VERSION ""

NS_ :

BS_:

BU_: DAS HANDCART DAS STEER STEER INVERTER_L HANDCART HANDCART DAS DAS STEER DAS BMS_HV STEER STEER HANDCART DAS TLM BMS_HV STEER STEER STEER DAS TLM DAS DAS HANDCART STEER STEER BMS_HV DAS BMS_HW HANDCART STEER DAS BMS_HV DAS STEER TLM DAS BMS_LW HANDCART STEER DAS STEER DAS STEER DAS STEER TLM DAS DAS DAS STEER STEER STEER STEER DAS BMS_HW DAS TLM DAS BMS_LV STEER DAS DAS TLM STEER BMS_LV TLM DAS BMS_HV STEER BMS_LV BMS_LV DATA_LOGGER DAS STEER BMS_HV STEER DAS BMS_LV TLM DAS BMS_HV STEER BMS_LV BMS_LV STEER DAS BMS_HV TLM STEER TLM BMS_LV STEER DAS STEER STEER TLM STEER BMS_HV BMS_LV DAS STEER STEER BMS_LV HANDCART HANDCART DAS BMS_HV BMS_LV DAS BMS_HV BMS_LV INVERTER_L STEER DAS HANDCART STEER BMS_HV BMS_HV BMS_LV DAS BMS_HV DAS STEER HANDCART BMS_HV STEER HANDCART INVERTER_L HANDCART TLM BMS_HV BMS_HV BMS_LV DAS HANDCART HANDCART DAS STEER BMS_HV STEER HANDCART HANDCART TLM BMS_HV BMS_HV BMS_LV DAS HANDCART DAS STEER BMS_HV STEER HANDCART HANDCART TLM BMS_HV BMS_HV BMS_HV DAS HANDCART DAS STEER BMS_HV STEER HANDCART HANDCART TLM HANDCART HANDCART BMS_HV BMS_HV BMS_LV HANDCART BMS_LV BMS_HV BMS_HV TLM HANDCART HANDCART STEER BMS_HV BMS_HV TLM HANDCART HANDCART BMS_HV BMS_HV BMS_HV HANDCART DAS HANDCART HANDCART BMS_HV STEER BMS_LV HANDCART BMS_HV HANDCART TLM DAS BMS_HV BMS_HV STEER HANDCART HANDCART BMS_HV BMS_HV HANDCART DAS HANDCART BMS_HV STEER DAS DAS BMS_HV HANDCART STEER DAS DAS DAS STEER HANDCART INVERTER_L BMS_HV DAS DAS DAS HANDCART STEER HANDCART STEER BMS_HV

BO_ 1818 NLG5_DIAG_TX: 8 NLG5
 SG_ LAD_D_ParamRp : 7|64@0+ (1,0) [0|0] "" Vector__XXX

BO_ 1816 NLG5_DIAG_RX: 8 Control
 SG_ LAD_D_ParamRq : 7|64@0+ (1,0) [0|0] "" Vector__XXX

BO_ 1556 NLG5_ERR: 5 NLG5
 SG_ NLG5_W_SC_M : 32|1@0+ (1,0) [0|0] ""  Control
 SG_ NLG5_W_OD : 33|1@0+ (1,0) [0|0] "" Vector__XXX
 SG_ NLG5_W_CM_NA : 35|1@0+ (1,0) [0|0] "" Vector__XXX
 SG_ NLG5_W_C_VOR : 36|1@0+ (1,0) [0|1] ""  Control
 SG_ NLG5_W_PL_IT : 37|1@0+ (1,0) [0|1] ""  Control
 SG_ NLG5_W_PL_BV : 38|1@0+ (1,0) [0|1] ""  Control
 SG_ NLG5_W_PL_MV : 39|1@0+ (1,0) [0|1] ""  Control
 SG_ NLG5_E_SDT_CT : 26|1@0+ (1,0) [0|1] ""  Control
 SG_ NLG5_E_SDT_AH : 27|1@0+ (1,0) [0|1] ""  Control
 SG_ NLG5_E_SDT_BV : 28|1@0+ (1,0) [0|1] ""  Control
 SG_ NLG5_E_SDT_BT : 29|1@0+ (1,0) [0|1] ""  Control
 SG_ NLG5_E_C_RX : 30|1@0+ (1,0) [0|1] ""  Control
 SG_ NLG5_E_C_TX : 31|1@0+ (1,0) [0|1] ""  Control
 SG_ NLG5_E_C_OFF : 16|1@0+ (1,0) [0|1] ""  Control
 SG_ NLG5_E_C_TO : 17|1@0+ (1,0) [0|1] ""  Control
 SG_ NLG5_E_INIT : 18|1@0+ (1,0) [0|1] ""  Control
 SG_ NLG5_E_WDT : 19|1@0+ (1,0) [0|1] ""  Control
 SG_ NLG5_E_EP_CRC : 20|1@0+ (1,0) [0|1] ""  Control
 SG_ NLG5_E_ES_CRC : 21|1@0+ (1,0) [0|1] ""  Control
 SG_ NLG5_E_NV_CRC : 22|1@0+ (1,0) [0|1] ""  Control
 SG_ NLG5_E_F_CRC : 23|1@0+ (1,0) [0|1] ""  Control
 SG_ NLG5_E_T_EXT3 : 8|1@0+ (1,0) [0|1] ""  Control
 SG_ NLG5_E_T_EXT2 : 9|1@0+ (1,0) [0|1] ""  Control
 SG_ NLG5_E_T_EXT1 : 10|1@0+ (1,0) [0|1] ""  Control
 SG_ NLG5_E_T_TR : 11|1@0+ (1,0) [0|1] ""  Control
 SG_ NLG5_E_T_DIO : 12|1@0+ (1,0) [0|1] ""  Control
 SG_ NLG5_E_T_POW : 13|1@0+ (1,0) [0|1] ""  Control
 SG_ NLG5_E_T_C : 14|1@0+ (1,0) [0|1] ""  Control
 SG_ NLG5_E_B_P : 15|1@0+ (1,0) [0|1] ""  Control
 SG_ NLG5_E_MF : 0|1@0+ (1,0) [0|1] ""  Control
 SG_ NLG5_E_OF : 1|1@0+ (1,0) [0|1] ""  Control
 SG_ NLG5_E_P_MV : 2|1@0+ (1,0) [0|1] ""  Control
 SG_ NLG5_E_P_OM : 3|1@0+ (1,0) [0|1] ""  Control
 SG_ NLG5_E_SC : 4|1@0+ (1,0) [0|1] ""  Control
 SG_ NLG5_E_MOV_I : 5|1@0+ (1,0) [0|1] ""  Control
 SG_ NLG5_E_MOV_II : 6|1@0+ (1,0) [0|1] ""  Control
 SG_ NLG5_E_OOV : 7|1@0+ (1,0) [0|1] ""  Control

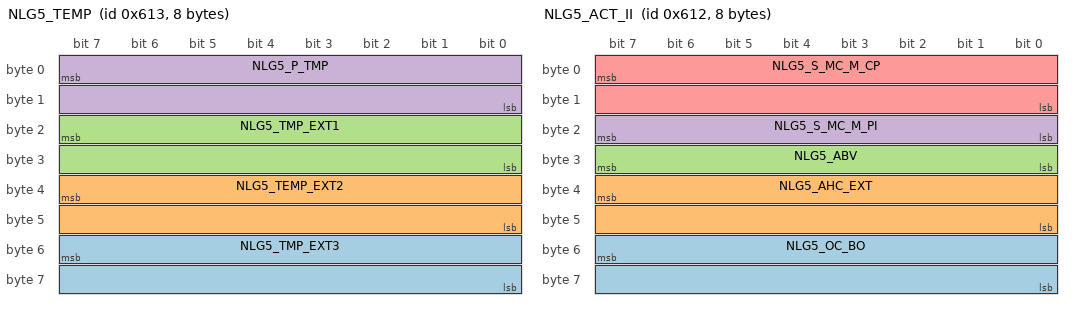
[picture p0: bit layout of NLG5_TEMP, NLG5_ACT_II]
BO_ 1555 NLG5_TEMP: 8 NLG5
 SG_ NLG5_TMP_EXT3 : 55|16@0- (0.1,0) [-40|300] "°C"  Control
 SG_ NLG5_TEMP_EXT2 : 39|16@0- (0.1,0) [-40|300] "°C"  Control
 SG_ NLG5_TMP_EXT1 : 23|16@0- (0.1,0) [-40|300] "°C"  Control
 SG_ NLG5_P_TMP : 7|16@0- (0.1,0) [-40|300] "°C"  Control

BO_ 1554 NLG5_ACT_II: 8 NLG5
 SG_ NLG5_OC_BO : 55|16@0+ (0.01,0) [0|50] "A"  Control
 SG_ NLG5_AHC_EXT : 39|16@0- (0.01,0) [-327.68|327.67] "Ah"  Control
 SG_ NLG5_ABV : 31|8@0+ (0.1,0) [0|25] "V"  Control
 SG_ NLG5_S_MC_M_PI : 23|8@0+ (0.1,0) [0|20] "A"  Control
 SG_ NLG5_S_MC_M_CP : 7|16@0+ (0.1,0) [0|100] "A"  Control

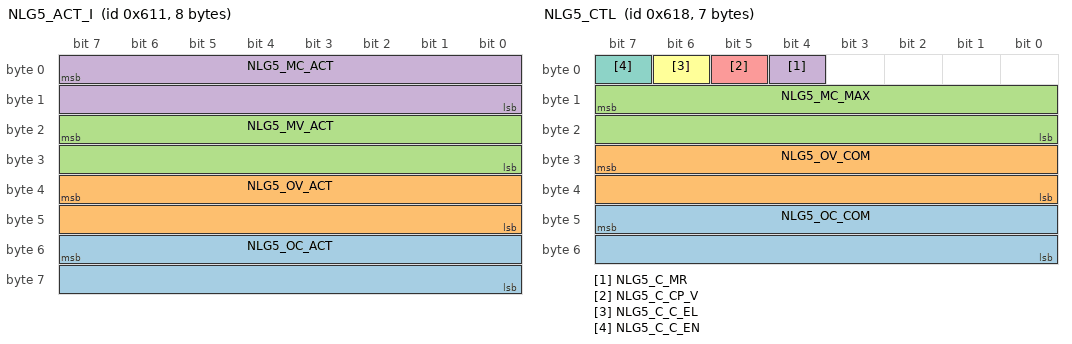
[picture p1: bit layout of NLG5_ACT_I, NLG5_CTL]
BO_ 1553 NLG5_ACT_I: 8 NLG5
 SG_ NLG5_OC_ACT : 55|16@0- (0.01,0) [0|150] "A"  Control
 SG_ NLG5_OV_ACT : 39|16@0+ (0.1,0) [0|1000] "V"  Control
 SG_ NLG5_MV_ACT : 23|16@0+ (0.1,0) [0|500] "V"  Control
 SG_ NLG5_MC_ACT : 7|16@0+ (0.01,0) [0|50] "A"  Control

BO_ 1552 NLG5_ST: 4 NLG5
 SG_ NLG5_S_AAC : 24|1@0+ (1,0) [0|1] ""  Control
 SG_ NLG5_S_L_T_BATT : 16|1@0+ (1,0) [0|1] ""  Control
 SG_ NLG5_S_L_T_TR : 17|1@0+ (1,0) [0|1] ""  Control
 SG_ NLG5_S_L_T_DIO : 18|1@0+ (1,0) [0|1] ""  Control
 SG_ NLG5_S_L_T_POW : 19|1@0+ (1,0) [0|1] ""  Control
 SG_ NLG5_S_L_T_CPRIM : 20|1@0+ (1,0) [0|1] ""  Control
 SG_ NLG5_S_L_MO_MAX : 21|1@0+ (1,0) [0|1] ""  Control
 SG_ NLG5_S_L_OC_MAX : 22|1@0+ (1,0) [0|1] ""  Control
 SG_ NLG5_S_L_MC_MAX : 23|1@0+ (1,0) [0|1] ""  Control
 SG_ NLG5_S_L_PMAX : 8|1@0+ (1,0) [0|1] ""  Control
 SG_ NLG5_S_L_CP : 9|1@0+ (1,0) [0|1] ""  Control
 SG_ NLG5_S_L_PI : 10|1@0+ (1,0) [0|1] ""  Control
 SG_ NLG5_S_L_MC : 11|1@0+ (1,0) [0|1] ""  Control
 SG_ NLG5_S_L_OC : 12|1@0+ (1,0) [0|1] ""  Control
 SG_ NLG5_S_L_OV : 13|1@0+ (1,0) [0|1] ""  Control
 SG_ NLG5_S_BPD_II : 14|1@0+ (1,0) [0|1] ""  Control
 SG_ NLG5_S_BPD_I : 15|1@0+ (1,0) [0|1] ""  Control
 SG_ NLG5_S_CP_DT : 0|1@0+ (1,0) [0|1] ""  Control
 SG_ NLG5_S_UM_II : 1|1@0+ (1,0) [0|1] ""  Control
 SG_ NLG5_S_UM_I : 2|1@0+ (1,0) [0|1] ""  Control
 SG_ NLG5_S_EUM : 3|1@0+ (1,0) [0|1] ""  Control
 SG_ NLG5_S_FAN : 4|1@0+ (1,0) [0|1] ""  Control
 SG_ NLG5_S_WAR : 5|1@0+ (1,0) [0|1] ""  Control
 SG_ NLG5_S_ERR : 6|1@0+ (1,0) [0|1] ""  Control
 SG_ NLG5_S_HE : 7|1@0+ (1,0) [0|1] ""  Control

BO_ 1560 NLG5_CTL: 7 Control
 SG_ NLG5_OC_COM : 47|16@0+ (0.1,0) [0|150] "A"  NLG5
 SG_ NLG5_OV_COM : 31|16@0+ (0.1,0) [0|1000] "V"  NLG5
 SG_ NLG5_MC_MAX : 15|16@0+ (0.1,0) [0|50] "A"  NLG5
 SG_ NLG5_C_MR : 4|1@0+ (1,0) [0|1] ""  NLG5
 SG_ NLG5_C_CP_V : 5|1@0+ (1,0) [0|1] ""  NLG5
 SG_ NLG5_C_C_EL : 6|1@0+ (1,0) [0|1] ""  NLG5
 SG_ NLG5_C_C_EN : 7|1@0+ (1,0) [0|1] ""  NLG5

BO_ 0 BMS_HV_JMP_TO_BLT: 0 Vector__XXX

BO_ 1 FLASH_BMS_HV_TX: 0 Vector__XXX

BO_ 2 FLASH_BMS_HV_RX: 0 Vector__XXX

BO_ 3 HV_CAN_FORWARD: 1 Vector__XXX
 SG_ can_forward_set : 0|1@1+ (1,0) [0|1] "" Vector__XXX

BO_ 4 FLASH_CELLBOARD_0_TX: 0 Vector__XXX

BO_ 5 FLASH_CELLBOARD_0_RX: 0 Vector__XXX

BO_ 6 FLASH_CELLBOARD_1_TX: 0 Vector__XXX

BO_ 7 FLASH_CELLBOARD_1_RX: 0 Vector__XXX

BO_ 8 FLASH_CELLBOARD_2_TX: 0 Vector__XXX

BO_ 9 FLASH_CELLBOARD_2_RX: 0 Vector__XXX

BO_ 10 FLASH_CELLBOARD_3_TX: 0 Vector__XXX

BO_ 11 FLASH_CELLBOARD_3_RX: 0 Vector__XXX

BO_ 12 FLASH_CELLBOARD_4_TX: 0 Vector__XXX

BO_ 13 FLASH_CELLBOARD_4_RX: 0 Vector__XXX

BO_ 14 FLASH_CELLBOARD_5_TX: 0 Vector__XXX

BO_ 15 FLASH_CELLBOARD_5_RX: 0 Vector__XXX

BO_ 16 BMS_LV_JMP_TO_BLT: 0 Vector__XXX

BO_ 17 FLASH_BMS_LV_TX: 0 Vector__XXX

BO_ 18 FLASH_BMS_LV_RX: 0 Vector__XXX

BO_ 19 ECU_JMP_TO_BLT: 0 Vector__XXX

BO_ 20 FLASH_ECU_TX: 0 Vector__XXX

BO_ 21 FLASH_ECU_RX: 0 Vector__XXX

BO_ 22 STEERING_JMP_TO_BLT: 0 Vector__XXX

BO_ 23 FLASH_STEERING_TX: 0 Vector__XXX

BO_ 24 FLASH_STEERING_RX: 0 Vector__XXX

BO_ 700 STEER_VERSION: 8 Vector__XXX
 SG_ canlib_build_time : 32|32@1+ (1,0) [0|4294967295] "" Vector__XXX
 SG_ component_build_time : 0|32@1+ (1,0) [0|4294967295] "" Vector__XXX

BO_ 701 DAS_VERSION: 8 Vector__XXX
 SG_ canlib_build_time : 32|32@1+ (1,0) [0|4294967295] "" Vector__XXX
 SG_ component_build_time : 0|32@1+ (1,0) [0|4294967295] "" Vector__XXX

BO_ 702 MAINBOARD_VERSION: 8 Vector__XXX
 SG_ canlib_build_time : 32|32@1+ (1,0) [0|4294967295] "" Vector__XXX
 SG_ component_build_time : 0|32@1+ (1,0) [0|4294967295] "" Vector__XXX

BO_ 703 LV_VERSION: 8 Vector__XXX
 SG_ canlib_build_time : 32|32@1+ (1,0) [0|4294967295] "" Vector__XXX
 SG_ component_build_time : 0|32@1+ (1,0) [0|4294967295] "" Vector__XXX

BO_ 704 TLM_VERSION: 8 Vector__XXX
 SG_ canlib_build_time : 32|32@1+ (1,0) [0|4294967295] "" Vector__XXX
 SG_ component_build_time : 0|32@1+ (1,0) [0|4294967295] "" Vector__XXX

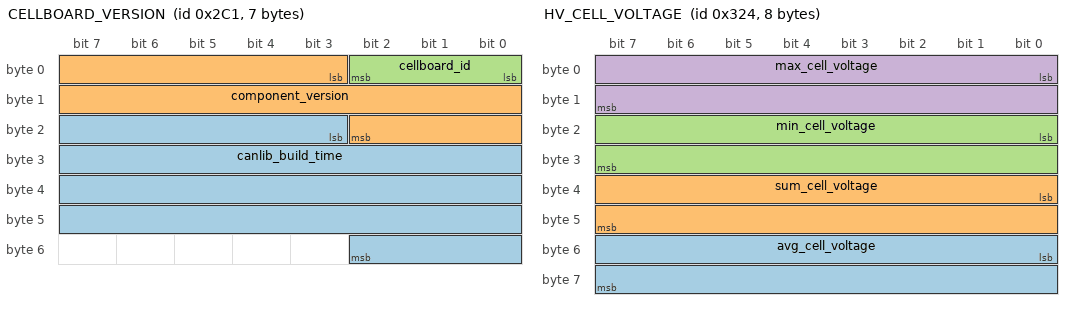
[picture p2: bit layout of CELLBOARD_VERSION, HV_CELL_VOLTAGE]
BO_ 705 CELLBOARD_VERSION: 7 Vector__XXX
 SG_ canlib_build_time : 19|32@1+ (1,0) [0|4294967295] "" Vector__XXX
 SG_ component_version : 3|16@1+ (1,0) [0|65535] "" Vector__XXX
 SG_ cellboard_id : 0|3@1+ (1,0) [0|7] "" Vector__XXX

BO_ 257 AMBIENT_TEMPERATURE: 2 Vector__XXX
 SG_ temp : 0|16@1- (1,-32768) [-32768|32767] "" Vector__XXX

BO_ 1072 DATA_LOGGER: 8 Vector__XXX
 SG_ placeholder2 : 32|32@1+ (1,0) [0|4294967295] "" Vector__XXX
 SG_ placeholder1 : 0|32@1+ (1,0) [0|4294967295] "" Vector__XXX

BO_ 265 SET_TLM_STATUS: 1 Vector__XXX
 SG_ tlm_status : 0|1@1+ (1,0) [0|1] "" Vector__XXX

BO_ 264 TLM_STATUS: 1 Vector__XXX
 SG_ tlm_status : 0|1@1+ (1,0) [0|1] "" Vector__XXX

BO_ 1801 STEER_SYSTEM_STATUS: 1 Vector__XXX
 SG_ soc_temp : 0|8@1+ (1,0) [0|255] "" Vector__XXX

BO_ 772 HV_VOLTAGE: 4 Vector__XXX
 SG_ bus_voltage : 16|16@1+ (0.9001956947162426,0) [0|460] "" Vector__XXX
 SG_ pack_voltage : 0|16@1+ (0.9001956947162426,0) [0|460] "" Vector__XXX

BO_ 804 HV_CELL_VOLTAGE: 8 Vector__XXX
 SG_ avg_cell_voltage : 48|16@1+ (7.629510948348211e-05,0) [0|5] "" Vector__XXX
 SG_ sum_cell_voltage : 32|16@1+ (0.007019150072480354,0) [0|460] "" Vector__XXX
 SG_ min_cell_voltage : 16|16@1+ (7.629510948348211e-05,0) [0|5] "" Vector__XXX
 SG_ max_cell_voltage : 0|16@1+ (7.629510948348211e-05,0) [0|5] "" Vector__XXX

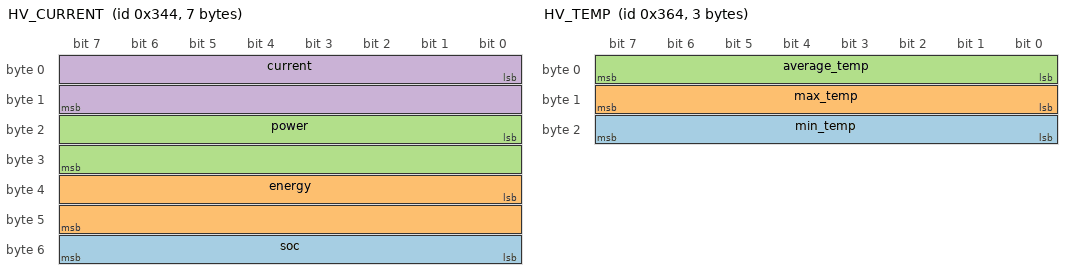
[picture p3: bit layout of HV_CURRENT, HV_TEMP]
BO_ 836 HV_CURRENT: 7 Vector__XXX
 SG_ soc : 48|8@1+ (0.39215686274509803,0) [0|100] "" Vector__XXX
 SG_ energy : 32|16@1+ (0.10681315327687495,0) [0|7000] "" Vector__XXX
 SG_ power : 16|16@1+ (0.0015259021896696422,0) [0|100] "" Vector__XXX
 SG_ current : 0|16@1+ (0.006103608758678569,-200) [-200|200] "" Vector__XXX

BO_ 868 HV_TEMP: 3 Vector__XXX
 SG_ min_temp : 16|8@1+ (0.39215686274509803,-20) [-20|80] "" Vector__XXX
 SG_ max_temp : 8|8@1+ (0.39215686274509803,-20) [-20|80] "" Vector__XXX
 SG_ average_temp : 0|8@1+ (0.39215686274509803,-20) [-20|80] "" Vector__XXX

BO_ 36 HV_ERRORS: 4 Vector__XXX
 SG_ errors_EEPROM_WRITE : 31|1@1+ (1,0) [0|1] "" Vector__XXX
 SG_ errors_EEPROM_COMM : 30|1@1+ (1,0) [0|1] "" Vector__XXX
 SG_ errors_FEEDBACK_CIRCUITRY : 29|1@1+ (1,0) [0|1] "" Vector__XXX
 SG_ errors_FEEDBACK : 28|1@1+ (1,0) [0|1] "" Vector__XXX
 SG_ errors_FANS_DISCONNECTED : 27|1@1+ (1,0) [0|1] "" Vector__XXX
 SG_ errors_CONNECTOR_DISCONNECTED : 26|1@1+ (1,0) [0|1] "" Vector__XXX
 SG_ errors_CELLBOARD_INTERNAL : 25|1@1+ (1,0) [0|1] "" Vector__XXX
 SG_ errors_CELLBOARD_COMM : 24|1@1+ (1,0) [0|1] "" Vector__XXX
 SG_ errors_INT_VOLTAGE_MISMATCH : 23|1@1+ (1,0) [0|1] "" Vector__XXX
 SG_ errors_CAN : 22|1@1+ (1,0) [0|1] "" Vector__XXX
 SG_ errors_OVER_CURRENT : 21|1@1+ (1,0) [0|1] "" Vector__XXX
 SG_ errors_CELL_OVER_TEMPERATURE : 20|1@1+ (1,0) [0|1] "" Vector__XXX
 SG_ errors_CELL_HIGH_TEMPERATURE : 19|1@1+ (1,0) [0|1] "" Vector__XXX
 SG_ errors_CELL_OVER_VOLTAGE : 18|1@1+ (1,0) [0|1] "" Vector__XXX
 SG_ errors_CELL_UNDER_VOLTAGE : 17|1@1+ (1,0) [0|1] "" Vector__XXX
 SG_ errors_CELL_LOW_VOLTAGE : 16|1@1+ (1,0) [0|1] "" Vector__XXX
 SG_ warnings_EEPROM_WRITE : 15|1@1+ (1,0) [0|1] "" Vector__XXX
 SG_ warnings_EEPROM_COMM : 14|1@1+ (1,0) [0|1] "" Vector__XXX
 SG_ warnings_FEEDBACK_CIRCUITRY : 13|1@1+ (1,0) [0|1] "" Vector__XXX
 SG_ warnings_FEEDBACK : 12|1@1+ (1,0) [0|1] "" Vector__XXX
 SG_ warnings_FANS_DISCONNECTED : 11|1@1+ (1,0) [0|1] "" Vector__XXX
 SG_ warnings_CONNECTOR_DISCONNECTED : 10|1@1+ (1,0) [0|1] "" Vector__XXX
 SG_ warnings_CELLBOARD_INTERNAL : 9|1@1+ (1,0) [0|1] "" Vector__XXX
 SG_ warnings_CELLBOARD_COMM : 8|1@1+ (1,0) [0|1] "" Vector__XXX
 SG_ warnings_INT_VOLTAGE_MISMATCH : 7|1@1+ (1,0) [0|1] "" Vector__XXX
 SG_ warnings_CAN : 6|1@1+ (1,0) [0|1] "" Vector__XXX
 SG_ warnings_OVER_CURRENT : 5|1@1+ (1,0) [0|1] "" Vector__XXX
 SG_ warnings_CELL_OVER_TEMPERATURE : 4|1@1+ (1,0) [0|1] "" Vector__XXX
 SG_ warnings_CELL_HIGH_TEMPERATURE : 3|1@1+ (1,0) [0|1] "" Vector__XXX
 SG_ warnings_CELL_OVER_VOLTAGE : 2|1@1+ (1,0) [0|1] "" Vector__XXX
 SG_ warnings_CELL_UNDER_VOLTAGE : 1|1@1+ (1,0) [0|1] "" Vector__XXX
 SG_ warnings_CELL_LOW_VOLTAGE : 0|1@1+ (1,0) [0|1] "" Vector__XXX

BO_ 260 HV_DEBUG_SIGNALS: 5 Vector__XXX
 SG_ debug_signals_ERROR_EEPROM_WRITE : 35|1@1+ (1,0) [0|1] "" Vector__XXX
 SG_ debug_signals_ERROR_EEPROM_COMM : 34|1@1+ (1,0) [0|1] "" Vector__XXX
 SG_ debug_signals_ERROR_FEEDBACK_CIRCUITRY : 33|1@1+ (1,0) [0|1] "" Vector__XXX
 SG_ debug_signals_ERROR_FEEDBACK : 32|1@1+ (1,0) [0|1] "" Vector__XXX
 SG_ debug_signals_ERROR_FANS_DISCONNECTED : 31|1@1+ (1,0) [0|1] "" Vector__XXX
 SG_ debug_signals_ERROR_CONNECTOR_DISCONNECTED : 30|1@1+ (1,0) [0|1] "" Vector__XXX
 SG_ debug_signals_ERROR_CELLBOARD_INTERNAL : 29|1@1+ (1,0) [0|1] "" Vector__XXX
 SG_ debug_signals_ERROR_CELLBOARD_COMM : 28|1@1+ (1,0) [0|1] "" Vector__XXX
 SG_ debug_signals_ERROR_INT_VOLTAGE_MISMATCH : 27|1@1+ (1,0) [0|1] "" Vector__XXX
 SG_ debug_signals_ERROR_CAN : 26|1@1+ (1,0) [0|1] "" Vector__XXX
 SG_ debug_signals_ERROR_OVER_CURRENT : 25|1@1+ (1,0) [0|1] "" Vector__XXX
 SG_ debug_signals_ERROR_CELL_OVER_TEMPERATURE : 24|1@1+ (1,0) [0|1] "" Vector__XXX
 SG_ debug_signals_ERROR_CELL_HIGH_TEMPERATURE : 23|1@1+ (1,0) [0|1] "" Vector__XXX
 SG_ debug_signals_ERROR_CELL_OVER_VOLTAGE : 22|1@1+ (1,0) [0|1] "" Vector__XXX
 SG_ debug_signals_ERROR_CELL_UNDER_VOLTAGE : 21|1@1+ (1,0) [0|1] "" Vector__XXX
 SG_ debug_signals_ERROR_CELL_LOW_VOLTAGE : 20|1@1+ (1,0) [0|1] "" Vector__XXX
 SG_ debug_signals_FEEDBACK_SD_IMD : 19|1@1+ (1,0) [0|1] "" Vector__XXX
 SG_ debug_signals_FEEDBACK_SD_BMS : 18|1@1+ (1,0) [0|1] "" Vector__XXX
 SG_ debug_signals_FEEDBACK_SD_IN : 17|1@1+ (1,0) [0|1] "" Vector__XXX
 SG_ debug_signals_FEEDBACK_SD_OUT : 16|1@1+ (1,0) [0|1] "" Vector__XXX
 SG_ debug_signals_FEEDBACK_SD_END : 15|1@1+ (1,0) [0|1] "" Vector__XXX
 SG_ debug_signals_FEEDBACK_CHECK_MUX : 14|1@1+ (1,0) [0|1] "" Vector__XXX
 SG_ debug_signals_FEEDBACK_IMD_FAULT : 13|1@1+ (1,0) [0|1] "" Vector__XXX
 SG_ debug_signals_FEEDBACK_TSP_OVER_60V_STATUS : 12|1@1+ (1,0) [0|1] "" Vector__XXX
 SG_ debug_signals_FEEDBACK_PRECHARGE_STATUS : 11|1@1+ (1,0) [0|1] "" Vector__XXX
 SG_ debug_signals_FEEDBACK_AIRN_GATE : 10|1@1+ (1,0) [0|1] "" Vector__XXX
 SG_ debug_signals_FEEDBACK_AIRP_GATE : 9|1@1+ (1,0) [0|1] "" Vector__XXX
 SG_ debug_signals_FEEDBACK_AIRP_STATUS : 8|1@1+ (1,0) [0|1] "" Vector__XXX
 SG_ debug_signals_FEEDBACK_AIRN_STATUS : 7|1@1+ (1,0) [0|1] "" Vector__XXX
 SG_ debug_signals_FEEDBACK_TS_OVER_60V_STATUS : 6|1@1+ (1,0) [0|1] "" Vector__XXX
 SG_ debug_signals_FEEDBACK_TSAL_GREEN : 5|1@1+ (1,0) [0|1] "" Vector__XXX
 SG_ debug_signals_FEEDBACK_EXT_LATCHED : 4|1@1+ (1,0) [0|1] "" Vector__XXX
 SG_ debug_signals_FEEDBACK_BMS_COCKPIT : 3|1@1+ (1,0) [0|1] "" Vector__XXX
 SG_ debug_signals_FEEDBACK_TSAL_GREEN_FAULT_LATCHED : 2|1@1+ (1,0) [0|1] "" Vector__XXX
 SG_ debug_signals_FEEDBACK_IMD_COCKPIT : 1|1@1+ (1,0) [0|1] "" Vector__XXX
 SG_ debug_signals_FEEDBACK_IMPLAUSIBILITY_DETECTED : 0|1@1+ (1,0) [0|1] "" Vector__XXX

BO_ 32 HV_FANS_OVERRIDE: 3 Vector__XXX
 SG_ fans_speed : 1|16@1+ (1.5259021896696422e-05,0) [0|1] "" Vector__XXX
 SG_ fans_override : 0|1@1+ (1,0) [0|1] "" Vector__XXX

BO_ 37 HV_CAN_FORWARD_STATUS: 1 Vector__XXX
 SG_ can_forward_status : 0|1@1+ (1,0) [0|1] "" Vector__XXX

BO_ 773 HV_FANS_OVERRIDE_STATUS: 3 Vector__XXX
 SG_ fans_speed : 1|16@1+ (1.5259021896696422e-05,0) [0|1] "" Vector__XXX
 SG_ fans_override : 0|1@1+ (1,0) [0|1] "" Vector__XXX

BO_ 771 HV_FEEDBACK_STATUS: 5 Vector__XXX
 SG_ feedback_sd_imd : 38|2@1+ (1,0) [0|3] "" Vector__XXX
 SG_ feedback_sd_bms : 36|2@1+ (1,0) [0|3] "" Vector__XXX
 SG_ feedback_sd_in : 34|2@1+ (1,0) [0|3] "" Vector__XXX
 SG_ feedback_sd_out : 32|2@1+ (1,0) [0|3] "" Vector__XXX
 SG_ feedback_sd_end : 30|2@1+ (1,0) [0|3] "" Vector__XXX
 SG_ feedback_check_mux : 28|2@1+ (1,0) [0|3] "" Vector__XXX
 SG_ feedback_imd_fault : 26|2@1+ (1,0) [0|3] "" Vector__XXX
 SG_ feedback_tsp_over_60v_status : 24|2@1+ (1,0) [0|3] "" Vector__XXX
 SG_ feedback_precharge_status : 22|2@1+ (1,0) [0|3] "" Vector__XXX
 SG_ feedback_airn_gate : 20|2@1+ (1,0) [0|3] "" Vector__XXX
 SG_ feedback_airp_gate : 18|2@1+ (1,0) [0|3] "" Vector__XXX
 SG_ feedback_airp_status : 16|2@1+ (1,0) [0|3] "" Vector__XXX
 SG_ feedback_airn_status : 14|2@1+ (1,0) [0|3] "" Vector__XXX
 SG_ feedback_ts_over_60v_status : 12|2@1+ (1,0) [0|3] "" Vector__XXX
 SG_ feedback_tsal_green : 10|2@1+ (1,0) [0|3] "" Vector__XXX
 SG_ feedback_ext_latched : 8|2@1+ (1,0) [0|3] "" Vector__XXX
 SG_ feedback_bms_cockpit : 6|2@1+ (1,0) [0|3] "" Vector__XXX
 SG_ feedback_tsal_green_fault_latched : 4|2@1+ (1,0) [0|3] "" Vector__XXX
 SG_ feedback_imd_cockpit : 2|2@1+ (1,0) [0|3] "" Vector__XXX
 SG_ feedback_implausibility_detected : 0|2@1+ (1,0) [0|3] "" Vector__XXX

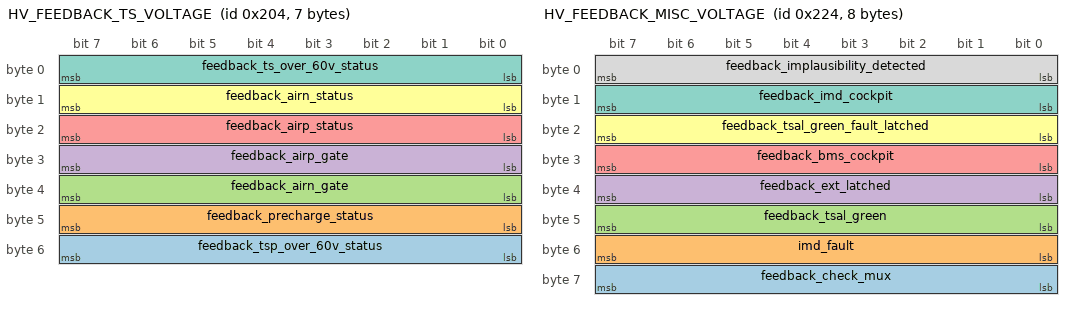
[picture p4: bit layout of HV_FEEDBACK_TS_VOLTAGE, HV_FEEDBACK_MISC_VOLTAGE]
BO_ 516 HV_FEEDBACK_TS_VOLTAGE: 7 Vector__XXX
 SG_ feedback_tsp_over_60v_status : 48|8@1+ (0.012941176470588235,0) [0|3.3] "" Vector__XXX
 SG_ feedback_precharge_status : 40|8@1+ (0.012941176470588235,0) [0|3.3] "" Vector__XXX
 SG_ feedback_airn_gate : 32|8@1+ (0.012941176470588235,0) [0|3.3] "" Vector__XXX
 SG_ feedback_airp_gate : 24|8@1+ (0.012941176470588235,0) [0|3.3] "" Vector__XXX
 SG_ feedback_airp_status : 16|8@1+ (0.012941176470588235,0) [0|3.3] "" Vector__XXX
 SG_ feedback_airn_status : 8|8@1+ (0.012941176470588235,0) [0|3.3] "" Vector__XXX
 SG_ feedback_ts_over_60v_status : 0|8@1+ (0.012941176470588235,0) [0|3.3] "" Vector__XXX

BO_ 548 HV_FEEDBACK_MISC_VOLTAGE: 8 Vector__XXX
 SG_ feedback_check_mux : 56|8@1+ (0.012941176470588235,0) [0|3.3] "" Vector__XXX
 SG_ imd_fault : 48|8@1+ (0.012941176470588235,0) [0|3.3] "" Vector__XXX
 SG_ feedback_tsal_green : 40|8@1+ (0.012941176470588235,0) [0|3.3] "" Vector__XXX
 SG_ feedback_ext_latched : 32|8@1+ (0.012941176470588235,0) [0|3.3] "" Vector__XXX
 SG_ feedback_bms_cockpit : 24|8@1+ (0.012941176470588235,0) [0|3.3] "" Vector__XXX
 SG_ feedback_tsal_green_fault_latched : 16|8@1+ (0.012941176470588235,0) [0|3.3] "" Vector__XXX
 SG_ feedback_imd_cockpit : 8|8@1+ (0.012941176470588235,0) [0|3.3] "" Vector__XXX
 SG_ feedback_implausibility_detected : 0|8@1+ (0.012941176470588235,0) [0|3.3] "" Vector__XXX

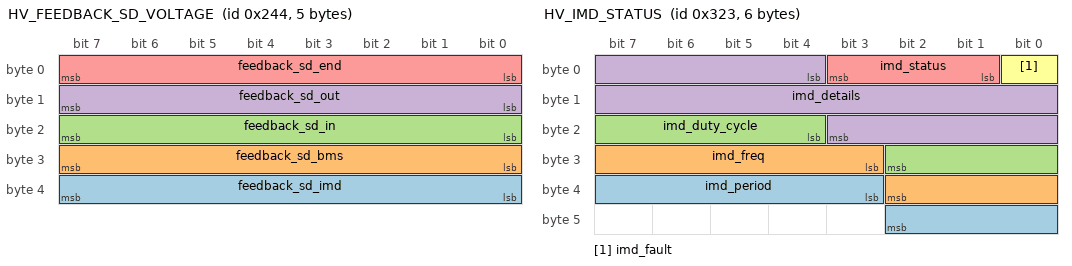
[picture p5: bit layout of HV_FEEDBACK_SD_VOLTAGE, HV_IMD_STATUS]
BO_ 580 HV_FEEDBACK_SD_VOLTAGE: 5 Vector__XXX
 SG_ feedback_sd_imd : 32|8@1+ (0.012941176470588235,0) [0|3.3] "" Vector__XXX
 SG_ feedback_sd_bms : 24|8@1+ (0.012941176470588235,0) [0|3.3] "" Vector__XXX
 SG_ feedback_sd_in : 16|8@1+ (0.012941176470588235,0) [0|3.3] "" Vector__XXX
 SG_ feedback_sd_out : 8|8@1+ (0.012941176470588235,0) [0|3.3] "" Vector__XXX
 SG_ feedback_sd_end : 0|8@1+ (0.012941176470588235,0) [0|3.3] "" Vector__XXX

BO_ 803 HV_IMD_STATUS: 6 Vector__XXX
 SG_ imd_period : 35|8@1+ (1,0) [0|255] "" Vector__XXX
 SG_ imd_freq : 27|8@1+ (1,0) [0|255] "" Vector__XXX
 SG_ imd_duty_cycle : 20|7@1+ (1,0) [0|100] "" Vector__XXX
 SG_ imd_details : 4|16@1+ (1,0) [0|65535] "" Vector__XXX
 SG_ imd_status : 1|3@1+ (1,0) [0|7] "" Vector__XXX
 SG_ imd_fault : 0|1@1+ (1,0) [0|1] "" Vector__XXX

BO_ 84 TS_STATUS: 1 Vector__XXX
 SG_ ts_status : 0|3@1+ (1,0) [0|7] "" Vector__XXX

BO_ 82 SET_TS_STATUS_DAS: 1 Vector__XXX
 SG_ ts_status_set : 0|1@1+ (1,0) [0|1] "" Vector__XXX

BO_ 83 SET_TS_STATUS_HANDCART: 1 Vector__XXX
 SG_ ts_status_set : 0|1@1+ (1,0) [0|1] "" Vector__XXX

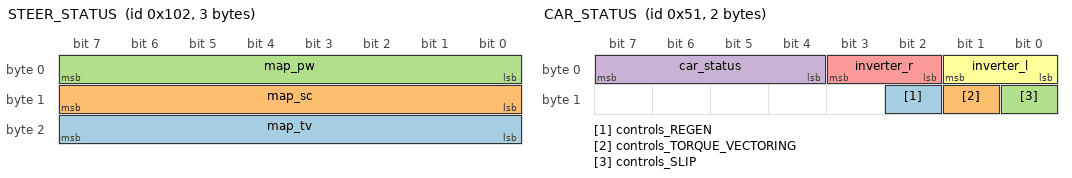
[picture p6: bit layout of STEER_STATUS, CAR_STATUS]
BO_ 258 STEER_STATUS: 3 Vector__XXX
 SG_ map_tv : 16|8@1+ (0.01,0) [0|1] "" Vector__XXX
 SG_ map_sc : 8|8@1+ (0.01,0) [0|1] "" Vector__XXX
 SG_ map_pw : 0|8@1+ (0.01,-0.5) [-0.5|1] "" Vector__XXX

BO_ 80 SET_CAR_STATUS: 1 Vector__XXX
 SG_ car_status_set : 0|2@1+ (1,0) [0|3] "" Vector__XXX

BO_ 1026 SET_PEDAL_CALIBRATION: 1 Vector__XXX
 SG_ bound : 1|1@1+ (1,0) [0|1] "" Vector__XXX
 SG_ pedal : 0|1@1+ (1,0) [0|1] "" Vector__XXX

BO_ 1032 PEDAL_CALIBRATION_ACK: 1 Vector__XXX
 SG_ bound : 1|1@1+ (1,0) [0|1] "" Vector__XXX
 SG_ pedal : 0|1@1+ (1,0) [0|1] "" Vector__XXX

BO_ 81 CAR_STATUS: 2 Vector__XXX
 SG_ controls_REGEN : 10|1@1+ (1,0) [0|1] "" Vector__XXX
 SG_ controls_TORQUE_VECTORING : 9|1@1+ (1,0) [0|1] "" Vector__XXX
 SG_ controls_SLIP : 8|1@1+ (1,0) [0|1] "" Vector__XXX
 SG_ car_status : 4|4@1+ (1,0) [0|15] "" Vector__XXX
 SG_ inverter_r : 2|2@1+ (1,0) [0|3] "" Vector__XXX
 SG_ inverter_l : 0|2@1+ (1,0) [0|3] "" Vector__XXX

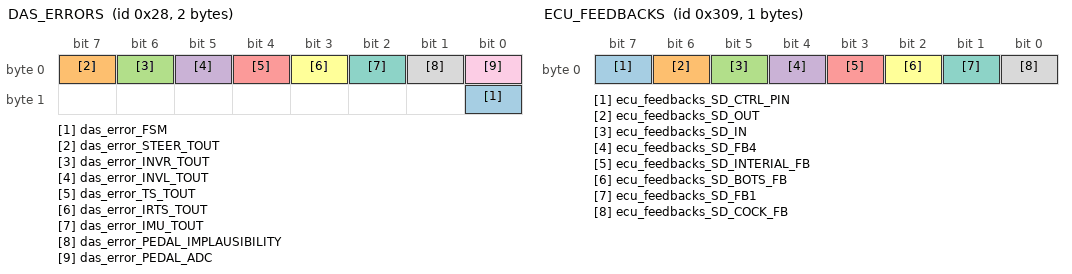
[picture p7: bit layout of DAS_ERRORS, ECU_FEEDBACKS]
BO_ 40 DAS_ERRORS: 2 Vector__XXX
 SG_ das_error_FSM : 8|1@1+ (1,0) [0|1] "" Vector__XXX
 SG_ das_error_STEER_TOUT : 7|1@1+ (1,0) [0|1] "" Vector__XXX
 SG_ das_error_INVR_TOUT : 6|1@1+ (1,0) [0|1] "" Vector__XXX
 SG_ das_error_INVL_TOUT : 5|1@1+ (1,0) [0|1] "" Vector__XXX
 SG_ das_error_TS_TOUT : 4|1@1+ (1,0) [0|1] "" Vector__XXX
 SG_ das_error_IRTS_TOUT : 3|1@1+ (1,0) [0|1] "" Vector__XXX
 SG_ das_error_IMU_TOUT : 2|1@1+ (1,0) [0|1] "" Vector__XXX
 SG_ das_error_PEDAL_IMPLAUSIBILITY : 1|1@1+ (1,0) [0|1] "" Vector__XXX
 SG_ das_error_PEDAL_ADC : 0|1@1+ (1,0) [0|1] "" Vector__XXX

BO_ 777 ECU_FEEDBACKS: 1 Vector__XXX
 SG_ ecu_feedbacks_SD_CTRL_PIN : 7|1@1+ (1,0) [0|1] "" Vector__XXX
 SG_ ecu_feedbacks_SD_OUT : 6|1@1+ (1,0) [0|1] "" Vector__XXX
 SG_ ecu_feedbacks_SD_IN : 5|1@1+ (1,0) [0|1] "" Vector__XXX
 SG_ ecu_feedbacks_SD_FB4 : 4|1@1+ (1,0) [0|1] "" Vector__XXX
 SG_ ecu_feedbacks_SD_INTERIAL_FB : 3|1@1+ (1,0) [0|1] "" Vector__XXX
 SG_ ecu_feedbacks_SD_BOTS_FB : 2|1@1+ (1,0) [0|1] "" Vector__XXX
 SG_ ecu_feedbacks_SD_FB1 : 1|1@1+ (1,0) [0|1] "" Vector__XXX
 SG_ ecu_feedbacks_SD_COCK_FB : 0|1@1+ (1,0) [0|1] "" Vector__XXX

BO_ 809 LV_STATUS: 1 Vector__XXX
 SG_ status : 0|2@1+ (1,0) [0|3] "" Vector__XXX

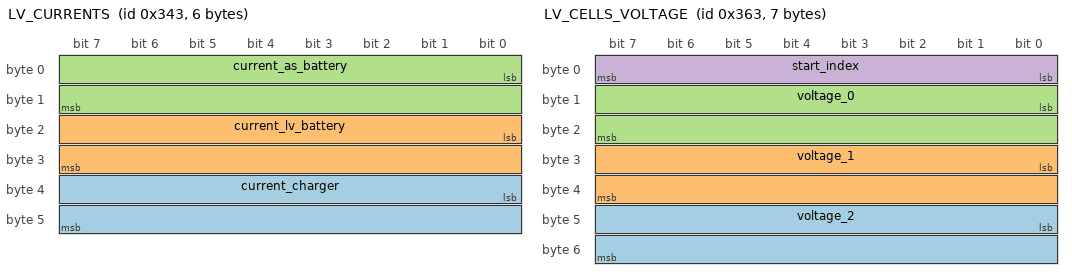
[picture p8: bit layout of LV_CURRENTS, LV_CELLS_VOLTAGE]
BO_ 835 LV_CURRENTS: 6 Vector__XXX
 SG_ current_charger : 32|16@1+ (0.0009155413138017853,-30) [-30|30] "" Vector__XXX
 SG_ current_lv_battery : 16|16@1+ (0.0009155413138017853,-10) [-10|50] "" Vector__XXX
 SG_ current_as_battery : 0|16@1+ (0.0009155413138017853,-10) [-10|50] "" Vector__XXX

BO_ 867 LV_CELLS_VOLTAGE: 7 Vector__XXX
 SG_ voltage_2 : 40|16@1+ (7.629510948348211e-05,0) [0|5] "" Vector__XXX
 SG_ voltage_1 : 24|16@1+ (7.629510948348211e-05,0) [0|5] "" Vector__XXX
 SG_ voltage_0 : 8|16@1+ (7.629510948348211e-05,0) [0|5] "" Vector__XXX
 SG_ start_index : 0|8@1+ (1,0) [0|255] "" Vector__XXX

BO_ 899 LV_TOTAL_VOLTAGE: 4 Vector__XXX
 SG_ total_voltage : 0|32@1+ (9.918250725748923e-05,0) [0|26] "" Vector__XXX

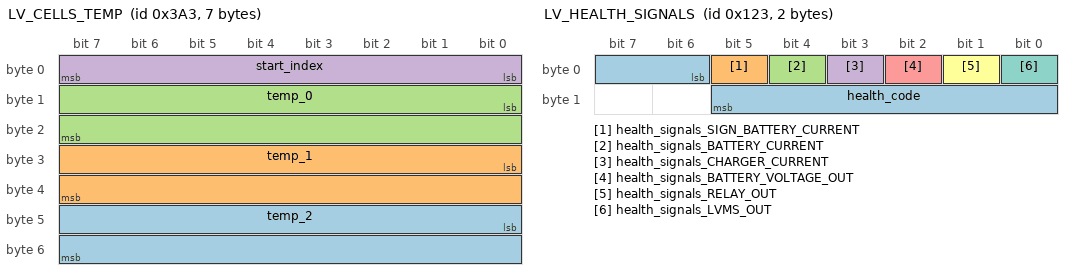
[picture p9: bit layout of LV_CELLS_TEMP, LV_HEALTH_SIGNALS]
BO_ 931 LV_CELLS_TEMP: 7 Vector__XXX
 SG_ temp_2 : 40|16@1+ (0.0061038881767686015,-20) [-20|80] "" Vector__XXX
 SG_ temp_1 : 24|16@1+ (0.0061038881767686015,-20) [-20|80] "" Vector__XXX
 SG_ temp_0 : 8|16@1+ (0.0061038881767686015,-20) [-20|80] "" Vector__XXX
 SG_ start_index : 0|8@1+ (1,0) [0|255] "" Vector__XXX

BO_ 963 COOLING_STATUS: 4 Vector__XXX
 SG_ pumps_speed : 16|16@1+ (3.0518043793392844e-05,-1) [-1|1] "" Vector__XXX
 SG_ radiators_speed : 0|16@1+ (3.0518043793392844e-05,-1) [-1|1] "" Vector__XXX

BO_ 775 SET_RADIATOR_SPEED: 2 Vector__XXX
 SG_ radiators_speed : 0|16@1+ (3.0518043793392844e-05,-1) [-1|1] "" Vector__XXX

BO_ 807 SET_PUMPS_SPEED: 2 Vector__XXX
 SG_ pumps_speed : 0|16@1+ (3.0518043793392844e-05,-1) [-1|1] "" Vector__XXX

BO_ 263 SET_INVERTER_CONNECTION_STATUS: 1 Vector__XXX
 SG_ status : 0|1@1+ (1,0) [0|1] "" Vector__XXX

BO_ 259 INVERTER_CONNECTION_STATUS: 1 Vector__XXX
 SG_ status : 0|1@1+ (1,0) [0|1] "" Vector__XXX

BO_ 515 LV_ERRORS: 5 Vector__XXX
 SG_ errors_MUX : 33|1@1+ (1,0) [0|1] "" Vector__XXX
 SG_ errors_ADC_INIT : 32|1@1+ (1,0) [0|1] "" Vector__XXX
 SG_ errors_PUMP : 31|1@1+ (1,0) [0|1] "" Vector__XXX
 SG_ errors_FAN : 30|1@1+ (1,0) [0|1] "" Vector__XXX
 SG_ errors_RADIATOR : 29|1@1+ (1,0) [0|1] "" Vector__XXX
 SG_ errors_MCP23017 : 28|1@1+ (1,0) [0|1] "" Vector__XXX
 SG_ errors_VOLTAGES_NOT_READY : 27|1@1+ (1,0) [0|1] "" Vector__XXX
 SG_ errors_BMS_MONITOR : 26|1@1+ (1,0) [0|1] "" Vector__XXX
 SG_ errors_RELAY : 25|1@1+ (1,0) [0|1] "" Vector__XXX
 SG_ errors_CELL_OVER_TEMPERATURE : 24|1@1+ (1,0) [0|1] "" Vector__XXX
 SG_ errors_CELL_UNDER_TEMPERATURE : 23|1@1+ (1,0) [0|1] "" Vector__XXX
 SG_ errors_OVER_CURRENT : 22|1@1+ (1,0) [0|1] "" Vector__XXX
 SG_ errors_SPI : 21|1@1+ (1,0) [0|1] "" Vector__XXX
 SG_ errors_CAN : 20|1@1+ (1,0) [0|1] "" Vector__XXX
 SG_ errors_BATTERY_OPEN_WIRE : 19|1@1+ (1,0) [0|1] "" Vector__XXX
 SG_ errors_CELL_OVERVOLTAGE : 18|1@1+ (1,0) [0|1] "" Vector__XXX
 SG_ errors_CELL_UNDERVOLTAGE : 17|1@1+ (1,0) [0|1] "" Vector__XXX
 SG_ warnings_MUX : 16|1@1+ (1,0) [0|1] "" Vector__XXX
 SG_ warnings_ADC_INIT : 15|1@1+ (1,0) [0|1] "" Vector__XXX
 SG_ warnings_PUMP : 14|1@1+ (1,0) [0|1] "" Vector__XXX
 SG_ warnings_FAN : 13|1@1+ (1,0) [0|1] "" Vector__XXX
 SG_ warnings_RADIATOR : 12|1@1+ (1,0) [0|1] "" Vector__XXX
 SG_ warnings_MCP23017 : 11|1@1+ (1,0) [0|1] "" Vector__XXX
 SG_ warnings_VOLTAGES_NOT_READY : 10|1@1+ (1,0) [0|1] "" Vector__XXX
 SG_ warnings_BMS_MONITOR : 9|1@1+ (1,0) [0|1] "" Vector__XXX
 SG_ warnings_RELAY : 8|1@1+ (1,0) [0|1] "" Vector__XXX
 SG_ warnings_CELL_OVER_TEMPERATURE : 7|1@1+ (1,0) [0|1] "" Vector__XXX
 SG_ warnings_CELL_UNDER_TEMPERATURE : 6|1@1+ (1,0) [0|1] "" Vector__XXX
 SG_ warnings_OVER_CURRENT : 5|1@1+ (1,0) [0|1] "" Vector__XXX
 SG_ warnings_SPI : 4|1@1+ (1,0) [0|1] "" Vector__XXX
 SG_ warnings_CAN : 3|1@1+ (1,0) [0|1] "" Vector__XXX
 SG_ warnings_BATTERY_OPEN_WIRE : 2|1@1+ (1,0) [0|1] "" Vector__XXX
 SG_ warnings_CELL_OVERVOLTAGE : 1|1@1+ (1,0) [0|1] "" Vector__XXX
 SG_ warnings_CELL_UNDERVOLTAGE : 0|1@1+ (1,0) [0|1] "" Vector__XXX

BO_ 291 LV_HEALTH_SIGNALS: 2 Vector__XXX
 SG_ health_code : 6|8@1+ (1,0) [0|255] "" Vector__XXX
 SG_ health_signals_SIGN_BATTERY_CURRENT : 5|1@1+ (1,0) [0|1] "" Vector__XXX
 SG_ health_signals_BATTERY_CURRENT : 4|1@1+ (1,0) [0|1] "" Vector__XXX
 SG_ health_signals_CHARGER_CURRENT : 3|1@1+ (1,0) [0|1] "" Vector__XXX
 SG_ health_signals_BATTERY_VOLTAGE_OUT : 2|1@1+ (1,0) [0|1] "" Vector__XXX
 SG_ health_signals_RELAY_OUT : 1|1@1+ (1,0) [0|1] "" Vector__XXX
 SG_ health_signals_LVMS_OUT : 0|1@1+ (1,0) [0|1] "" Vector__XXX

BO_ 323 LV_FEEDBACKS: 7 Vector__XXX
 SG_ sd_end : 35|16@1+ (0.005862237420615535,0) [0|12] "" Vector__XXX
 SG_ sd_start : 19|16@1+ (0.005862237420615535,0) [0|12] "" Vector__XXX
 SG_ feedbacks_AS_ACTUATION_FB : 18|1@1+ (1,0) [0|1] "" Vector__XXX
 SG_ feedbacks_FAN_FB : 17|1@1+ (1,0) [0|1] "" Vector__XXX
 SG_ feedbacks_RADIATORS_FB : 16|1@1+ (1,0) [0|1] "" Vector__XXX
 SG_ feedbacks_SHUTDOWN_FB : 15|1@1+ (1,0) [0|1] "" Vector__XXX
 SG_ feedbacks_PUMPS_FB : 14|1@1+ (1,0) [0|1] "" Vector__XXX
 SG_ feedbacks_PCBS_FB : 13|1@1+ (1,0) [0|1] "" Vector__XXX
 SG_ feedbacks_INVERTERS_FB : 12|1@1+ (1,0) [0|1] "" Vector__XXX
 SG_ feedbacks_INTERLOCK_FB : 11|1@1+ (1,0) [0|1] "" Vector__XXX
 SG_ feedbacks_ASMS_FB : 10|1@1+ (1,0) [0|1] "" Vector__XXX
 SG_ feedbacks_AMS_FB : 9|1@1+ (1,0) [0|1] "" Vector__XXX
 SG_ feedbacks_INVC_INTERLOCK_FB : 8|1@1+ (1,0) [0|1] "" Vector__XXX
 SG_ feedbacks_BACK_PLATE_FB : 7|1@1+ (1,0) [0|1] "" Vector__XXX
 SG_ feedbacks_HV_ENCL_2_FB : 6|1@1+ (1,0) [0|1] "" Vector__XXX
 SG_ feedbacks_INVC_LID_FB : 5|1@1+ (1,0) [0|1] "" Vector__XXX
 SG_ feedbacks_LV_ENCL : 4|1@1+ (1,0) [0|1] "" Vector__XXX
 SG_ feedbacks_RES_FB : 3|1@1+ (1,0) [0|1] "" Vector__XXX
 SG_ feedbacks_LVMS_FB : 2|1@1+ (1,0) [0|1] "" Vector__XXX
 SG_ feedbacks_HVD_FB : 1|1@1+ (1,0) [0|1] "" Vector__XXX
 SG_ feedbacks_BSPD_FB : 0|1@1+ (1,0) [0|1] "" Vector__XXX

BO_ 355 SHUTDOWN_STATUS: 1 Vector__XXX
 SG_ output : 1|1@1+ (1,0) [0|1] "" Vector__XXX
 SG_ input : 0|1@1+ (1,0) [0|1] "" Vector__XXX

BO_ 1833 LV_CAN_FLASH_REQ: 0 Vector__XXX

BO_ 1865 LV_CAN_FLASH_ACK: 1 Vector__XXX
 SG_ response : 0|2@1+ (1,0) [0|3] "" Vector__XXX

BO_ 41 MARKER: 0 Vector__XXX

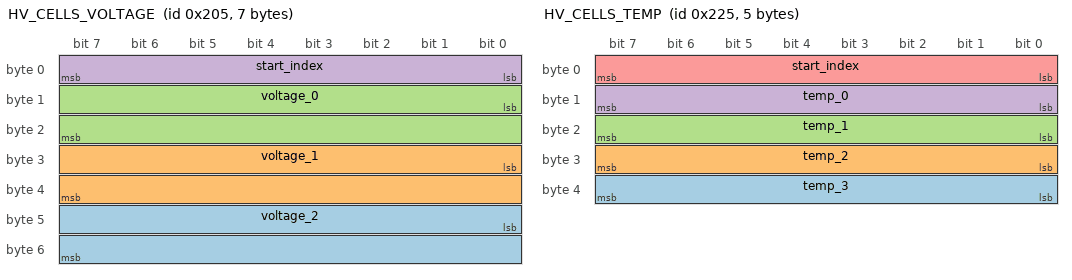
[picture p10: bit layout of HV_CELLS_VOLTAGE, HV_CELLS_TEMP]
BO_ 517 HV_CELLS_VOLTAGE: 7 Vector__XXX
 SG_ voltage_2 : 40|16@1+ (7.629510948348211e-05,0) [0|5] "" Vector__XXX
 SG_ voltage_1 : 24|16@1+ (7.629510948348211e-05,0) [0|5] "" Vector__XXX
 SG_ voltage_0 : 8|16@1+ (7.629510948348211e-05,0) [0|5] "" Vector__XXX
 SG_ start_index : 0|8@1+ (1,0) [0|255] "" Vector__XXX

BO_ 549 HV_CELLS_TEMP: 5 Vector__XXX
 SG_ temp_3 : 32|8@1+ (0.39215686274509803,-20) [-20|80] "" Vector__XXX
 SG_ temp_2 : 24|8@1+ (0.39215686274509803,-20) [-20|80] "" Vector__XXX
 SG_ temp_1 : 16|8@1+ (0.39215686274509803,-20) [-20|80] "" Vector__XXX
 SG_ temp_0 : 8|8@1+ (0.39215686274509803,-20) [-20|80] "" Vector__XXX
 SG_ start_index : 0|8@1+ (1,0) [0|255] "" Vector__XXX

BO_ 581 HV_CELL_BALANCING_STATUS: 4 Vector__XXX
 SG_ balancing_cells_CELL17 : 30|1@1+ (1,0) [0|1] "" Vector__XXX
 SG_ balancing_cells_CELL16 : 29|1@1+ (1,0) [0|1] "" Vector__XXX
 SG_ balancing_cells_CELL15 : 28|1@1+ (1,0) [0|1] "" Vector__XXX
 SG_ balancing_cells_CELL14 : 27|1@1+ (1,0) [0|1] "" Vector__XXX
 SG_ balancing_cells_CELL13 : 26|1@1+ (1,0) [0|1] "" Vector__XXX
 SG_ balancing_cells_CELL12 : 25|1@1+ (1,0) [0|1] "" Vector__XXX
 SG_ balancing_cells_CELL11 : 24|1@1+ (1,0) [0|1] "" Vector__XXX
 SG_ balancing_cells_CELL10 : 23|1@1+ (1,0) [0|1] "" Vector__XXX
 SG_ balancing_cells_CELL9 : 22|1@1+ (1,0) [0|1] "" Vector__XXX
 SG_ balancing_cells_CELL8 : 21|1@1+ (1,0) [0|1] "" Vector__XXX
 SG_ balancing_cells_CELL7 : 20|1@1+ (1,0) [0|1] "" Vector__XXX
 SG_ balancing_cells_CELL6 : 19|1@1+ (1,0) [0|1] "" Vector__XXX
 SG_ balancing_cells_CELL5 : 18|1@1+ (1,0) [0|1] "" Vector__XXX
 SG_ balancing_cells_CELL4 : 17|1@1+ (1,0) [0|1] "" Vector__XXX
 SG_ balancing_cells_CELL3 : 16|1@1+ (1,0) [0|1] "" Vector__XXX
 SG_ balancing_cells_CELL2 : 15|1@1+ (1,0) [0|1] "" Vector__XXX
 SG_ balancing_cells_CELL1 : 14|1@1+ (1,0) [0|1] "" Vector__XXX
 SG_ balancing_cells_CELL0 : 13|1@1+ (1,0) [0|1] "" Vector__XXX
 SG_ errors_OPEN_WIRE : 12|1@1+ (1,0) [0|1] "" Vector__XXX
 SG_ errors_TEMP_COMM_5 : 11|1@1+ (1,0) [0|1] "" Vector__XXX
 SG_ errors_TEMP_COMM_4 : 10|1@1+ (1,0) [0|1] "" Vector__XXX
 SG_ errors_TEMP_COMM_3 : 9|1@1+ (1,0) [0|1] "" Vector__XXX
 SG_ errors_TEMP_COMM_2 : 8|1@1+ (1,0) [0|1] "" Vector__XXX
 SG_ errors_TEMP_COMM_1 : 7|1@1+ (1,0) [0|1] "" Vector__XXX
 SG_ errors_TEMP_COMM_0 : 6|1@1+ (1,0) [0|1] "" Vector__XXX
 SG_ errors_LTC_COMM : 5|1@1+ (1,0) [0|1] "" Vector__XXX
 SG_ errors_CAN_COMM : 4|1@1+ (1,0) [0|1] "" Vector__XXX
 SG_ balancing_status : 3|1@1+ (1,0) [0|1] "" Vector__XXX
 SG_ cellboard_id : 0|3@1+ (1,0) [0|7] "" Vector__XXX

BO_ 512 SET_CELL_BALANCING_STATUS: 2 Vector__XXX
 SG_ balancing_threshold : 1|8@1+ (1,5) [5|200] "" Vector__XXX
 SG_ set_balancing_status : 0|1@1+ (1,0) [0|1] "" Vector__XXX

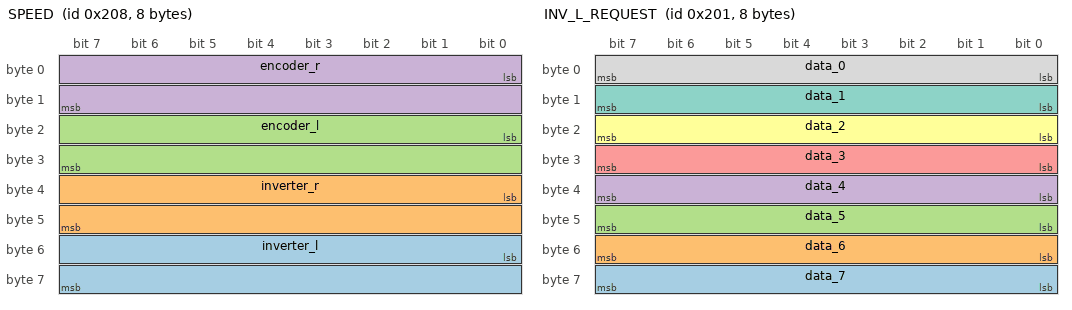
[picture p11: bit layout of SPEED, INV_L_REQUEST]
BO_ 520 SPEED: 8 Vector__XXX
 SG_ inverter_l : 48|16@1+ (0.006103608758678569,-200) [-200|200] "" Vector__XXX
 SG_ inverter_r : 32|16@1+ (0.006103608758678569,-200) [-200|200] "" Vector__XXX
 SG_ encoder_l : 16|16@1+ (0.006103608758678569,-200) [-200|200] "" Vector__XXX
 SG_ encoder_r : 0|16@1+ (0.006103608758678569,-200) [-200|200] "" Vector__XXX

BO_ 513 INV_L_REQUEST: 8 Vector__XXX
 SG_ data_7 : 56|8@1+ (1,0) [0|255] "" Vector__XXX
 SG_ data_6 : 48|8@1+ (1,0) [0|255] "" Vector__XXX
 SG_ data_5 : 40|8@1+ (1,0) [0|255] "" Vector__XXX
 SG_ data_4 : 32|8@1+ (1,0) [0|255] "" Vector__XXX
 SG_ data_3 : 24|8@1+ (1,0) [0|255] "" Vector__XXX
 SG_ data_2 : 16|8@1+ (1,0) [0|255] "" Vector__XXX
 SG_ data_1 : 8|8@1+ (1,0) [0|255] "" Vector__XXX
 SG_ data_0 : 0|8@1+ (1,0) [0|255] "" Vector__XXX

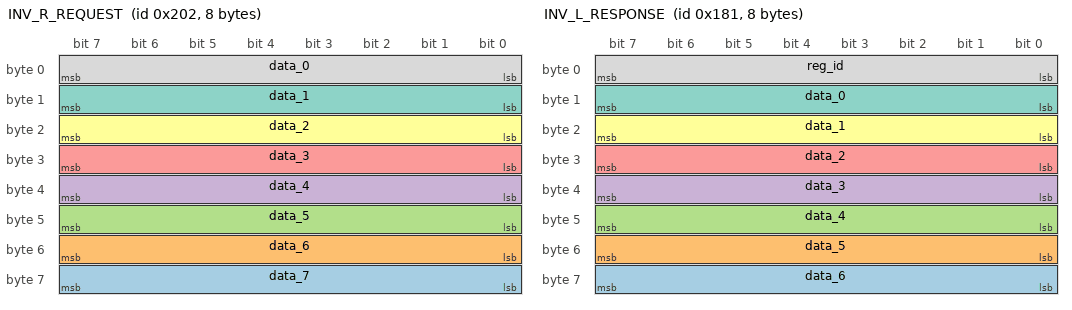
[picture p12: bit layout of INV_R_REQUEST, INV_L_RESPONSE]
BO_ 514 INV_R_REQUEST: 8 Vector__XXX
 SG_ data_7 : 56|8@1+ (1,0) [0|255] "" Vector__XXX
 SG_ data_6 : 48|8@1+ (1,0) [0|255] "" Vector__XXX
 SG_ data_5 : 40|8@1+ (1,0) [0|255] "" Vector__XXX
 SG_ data_4 : 32|8@1+ (1,0) [0|255] "" Vector__XXX
 SG_ data_3 : 24|8@1+ (1,0) [0|255] "" Vector__XXX
 SG_ data_2 : 16|8@1+ (1,0) [0|255] "" Vector__XXX
 SG_ data_1 : 8|8@1+ (1,0) [0|255] "" Vector__XXX
 SG_ data_0 : 0|8@1+ (1,0) [0|255] "" Vector__XXX

BO_ 385 INV_L_RESPONSE: 8 Vector__XXX
 SG_ data_6 : 56|8@1+ (1,0) [0|255] "" Vector__XXX
 SG_ data_5 : 48|8@1+ (1,0) [0|255] "" Vector__XXX
 SG_ data_4 : 40|8@1+ (1,0) [0|255] "" Vector__XXX
 SG_ data_3 : 32|8@1+ (1,0) [0|255] "" Vector__XXX
 SG_ data_2 : 24|8@1+ (1,0) [0|255] "" Vector__XXX
 SG_ data_1 : 16|8@1+ (1,0) [0|255] "" Vector__XXX
 SG_ data_0 : 8|8@1+ (1,0) [0|255] "" Vector__XXX
 SG_ reg_id : 0|8@1+ (1,0) [0|255] "" Vector__XXX

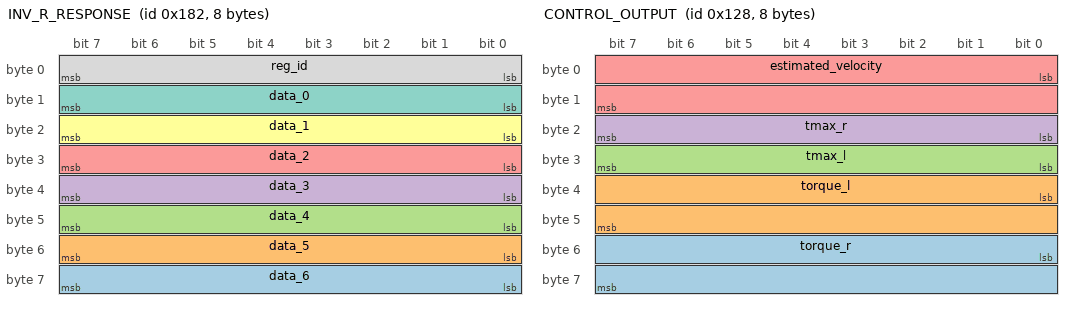
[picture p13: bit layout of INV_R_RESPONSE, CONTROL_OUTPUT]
BO_ 386 INV_R_RESPONSE: 8 Vector__XXX
 SG_ data_6 : 56|8@1+ (1,0) [0|255] "" Vector__XXX
 SG_ data_5 : 48|8@1+ (1,0) [0|255] "" Vector__XXX
 SG_ data_4 : 40|8@1+ (1,0) [0|255] "" Vector__XXX
 SG_ data_3 : 32|8@1+ (1,0) [0|255] "" Vector__XXX
 SG_ data_2 : 24|8@1+ (1,0) [0|255] "" Vector__XXX
 SG_ data_1 : 16|8@1+ (1,0) [0|255] "" Vector__XXX
 SG_ data_0 : 8|8@1+ (1,0) [0|255] "" Vector__XXX
 SG_ reg_id : 0|8@1+ (1,0) [0|255] "" Vector__XXX

BO_ 296 CONTROL_OUTPUT: 8 Vector__XXX
 SG_ torque_r : 48|16@1+ (0.0012207217517357137,0) [0|80] "" Vector__XXX
 SG_ torque_l : 32|16@1+ (0.0012207217517357137,0) [0|80] "" Vector__XXX
 SG_ tmax_l : 24|8@1+ (0.3137254901960784,0) [0|80] "" Vector__XXX
 SG_ tmax_r : 16|8@1+ (0.3137254901960784,0) [0|80] "" Vector__XXX
 SG_ estimated_velocity : 0|16@1+ (0.0009155413138017853,-10) [-10|50] "" Vector__XXX

BO_ 518 LC_RESET: 0 Vector__XXX

BO_ 768 HANDCART_STATUS: 1 Vector__XXX
 SG_ connected : 0|1@1+ (1,0) [0|1] "" Vector__XXX

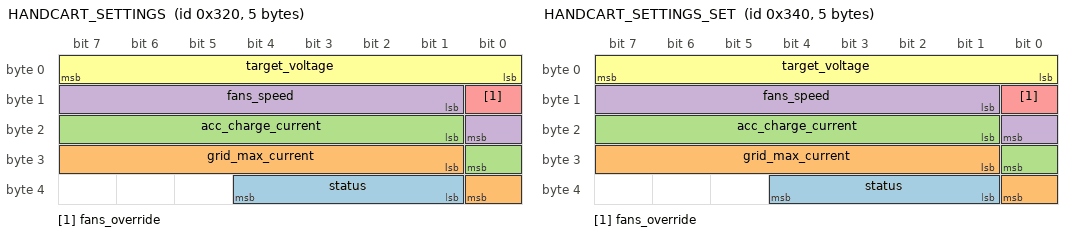
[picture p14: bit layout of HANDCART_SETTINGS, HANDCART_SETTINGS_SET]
BO_ 800 HANDCART_SETTINGS: 5 Vector__XXX
 SG_ status : 33|4@1+ (1,0) [0|15] "" Vector__XXX
 SG_ grid_max_current : 25|8@1+ (0.058823529411764705,1) [1|16] "" Vector__XXX
 SG_ acc_charge_current : 17|8@1+ (0.058823529411764705,1) [1|16] "" Vector__XXX
 SG_ fans_speed : 9|8@1+ (0.00392156862745098,0) [0|1] "" Vector__XXX
 SG_ fans_override : 8|1@1+ (1,0) [0|1] "" Vector__XXX
 SG_ target_voltage : 0|8@1+ (0.6039215686274509,300) [300|454] "" Vector__XXX

BO_ 832 HANDCART_SETTINGS_SET: 5 Vector__XXX
 SG_ status : 33|4@1+ (1,0) [0|15] "" Vector__XXX
 SG_ grid_max_current : 25|8@1+ (0.058823529411764705,1) [1|16] "" Vector__XXX
 SG_ acc_charge_current : 17|8@1+ (0.058823529411764705,1) [1|16] "" Vector__XXX
 SG_ fans_speed : 9|8@1+ (0.00392156862745098,0) [0|1] "" Vector__XXX
 SG_ fans_override : 8|1@1+ (1,0) [0|1] "" Vector__XXX
 SG_ target_voltage : 0|8@1+ (0.6039215686274509,300) [300|454] "" Vector__XXX

BO_ 547 SET_PTT_STATUS: 1 Vector__XXX
 SG_ status : 0|1@1+ (1,0) [0|1] "" Vector__XXX

BO_ 579 PTT_STATUS: 1 Vector__XXX
 SG_ status : 0|1@1+ (1,0) [0|1] "" Vector__XXX

BO_ 1027 REGEN_MANUAL_COMMAND: 3 Vector__XXX
 SG_ target : 1|16@1+ (0.0061038881767686015,0) [0|100] "" Vector__XXX
 SG_ status : 0|1@1+ (1,0) [0|1] "" Vector__XXX

CM_ SG_ 1818 LAD_D_ParamRp "Diag responded data to host";
CM_ SG_ 1816 LAD_D_ParamRq "Diag requested data from host";
CM_ SG_ 1556 NLG5_W_SC_M "Save-Charging-Mode reduces primary current to 3.95 A as long as one of the four internal temperature sensors indicates -18° C or less.
";
CM_ SG_ 1556 NLG5_W_OD "LED Output driver defective, LEDs can´t be controlled by NLG5 anymore. Charging is still possible.
";
CM_ SG_ 1556 NLG5_W_CM_NA "NLG5 Control message not active";
CM_ SG_ 1556 NLG5_W_C_VOR "Commanded value is out of specified range; max or min applicable value is assumed instead";
CM_ SG_ 1556 NLG5_W_PL_IT "Output power limited by charger internal overtemperature";
CM_ SG_ 1556 NLG5_W_PL_BV "Output power limited by low battery voltage";
CM_ SG_ 1556 NLG5_W_PL_MV "Output power limited by low mains voltage";
CM_ SG_ 1556 NLG5_E_SDT_CT "Emergency Shutdown Threshold 'Charging Time' is exceeded; see ChargeStar help section 'protective features';  error can only be cleared by cycling power ON-OFF-ON";
CM_ SG_ 1556 NLG5_E_SDT_AH "Emergency Shutdown Threshold 'Amp Hours' is exceeded; see ChargeStar help section 'protective features';  error can only be cleared by cycling power ON-OFF-ON";
CM_ SG_ 1556 NLG5_E_SDT_BV "Emergency Shutdown Threshold 'Battery Voltage' is exceeded; see ChargeStar help section 'protective features';  error can only be cleared by cycling power ON-OFF-ON";
CM_ SG_ 1556 NLG5_E_SDT_BT "Emergency Shutdown Threshold 'Battery Temperature' is exceeded; see ChargeStar help section 'protective features';  error can only be cleared by cycling power ON-OFF-ON";
CM_ SG_ 1556 NLG5_E_C_RX "CAN receiver buffer >127";
CM_ SG_ 1556 NLG5_E_C_TX "CAN transmit buffer >127";
CM_ SG_ 1556 NLG5_E_C_OFF "CAN off, transmit buffer >255";
CM_ SG_ 1556 NLG5_E_C_TO "CAN timeout, no control message received for >300ms";
CM_ SG_ 1556 NLG5_E_INIT "Initialization error";
CM_ SG_ 1556 NLG5_E_WDT "Internal Watchdog Timeout";
CM_ SG_ 1556 NLG5_E_EP_CRC "Pow EEPROM checksum failure";
CM_ SG_ 1556 NLG5_E_ES_CRC "Sys EEPROM checksum failure";
CM_ SG_ 1556 NLG5_E_NV_CRC "NVSRAM check sum failure; contains most of the scaling & calibration values, CAN ID's and  charging profile etc.";
CM_ SG_ 1556 NLG5_E_F_CRC "Flash memory checksum failure";
CM_ SG_ 1556 NLG5_E_T_EXT3 "Ext. temperature sensor 3 defective (if enabled)";
CM_ SG_ 1556 NLG5_E_T_EXT2 "Ext. temperature sensor 2 defective (if enabled)";
CM_ SG_ 1556 NLG5_E_T_EXT1 "Ext. temperature sensor 1 defective (if enabled)";
CM_ SG_ 1556 NLG5_E_T_TR "Temperature sensor for transformer defective";
CM_ SG_ 1556 NLG5_E_T_DIO "Temperature sensor for diodes defective";
CM_ SG_ 1556 NLG5_E_T_POW "Temperature sensor for prim power stage defective";
CM_ SG_ 1556 NLG5_E_T_C "Temperature sensor for prim capacitor defective";
CM_ SG_ 1556 NLG5_E_B_P "wrong battery polarity;  error can only be cleared by cycling power ON-OFF-ON";
CM_ SG_ 1556 NLG5_E_MF "Mains fuse defective";
CM_ SG_ 1556 NLG5_E_OF "output fuse defective";
CM_ SG_ 1556 NLG5_E_P_MV "plausibility mains voltage measurement wrong";
CM_ SG_ 1556 NLG5_E_P_OM "plausibility battery output voltage measurement wrong";
CM_ SG_ 1556 NLG5_E_SC "power stage short circuit condition detected; error can only be cleared by cycling power ON-OFF-ON";
CM_ SG_ 1556 NLG5_E_MOV_I "Mains overvoltage 1 detected";
CM_ SG_ 1556 NLG5_E_MOV_II "Mains overvoltage 2 detected";
CM_ SG_ 1556 NLG5_E_OOV "battery output overvoltage; error can only be cleared by cycling power ON-OFF-ON 
";
CM_ SG_ 1555 NLG5_TMP_EXT3 "Value of external battery temperature sensor #3 (if connected and enabled)";
CM_ SG_ 1555 NLG5_TEMP_EXT2 "Value of external battery temperature sensor #2 (if connected and enabled)";
CM_ SG_ 1555 NLG5_TMP_EXT1 "Value of external battery temperature sensor #1 (if connected and enabled)";
CM_ SG_ 1555 NLG5_P_TMP "Power stage temperature";
CM_ SG_ 1554 NLG5_OC_BO "output current of the booster (if one is present and active)";
CM_ SG_ 1554 NLG5_AHC_EXT "Charge balance obtained via  Ext. Ah counter connected to DI1 / DI2";
CM_ SG_ 1554 NLG5_ABV "Aux battery voltage";
CM_ SG_ 1554 NLG5_S_MC_M_PI "Value of mains current limit, commanded by the 'power indicator' (PI) analog input signal";
CM_ SG_ 1554 NLG5_S_MC_M_CP "Value of mains current limit, commanded by the control pilot (SAE J1772) signal";
CM_ SG_ 1553 NLG5_OC_ACT "output current to the battery";
CM_ SG_ 1553 NLG5_OV_ACT "Actual battery output voltage";
CM_ SG_ 1553 NLG5_MV_ACT "Actual mains voltage";
CM_ SG_ 1553 NLG5_MC_ACT "Actual mains current";
CM_ SG_ 1552 NLG5_S_AAC "AUX 12 V Automatic Charging Active";
CM_ SG_ 1552 NLG5_S_L_T_BATT "Output power limited by battery temperature";
CM_ SG_ 1552 NLG5_S_L_T_TR "Output power limited by temperature of transformer";
CM_ SG_ 1552 NLG5_S_L_T_DIO "Output power limited by temperature of diodes";
CM_ SG_ 1552 NLG5_S_L_T_POW "Output power limited by temperature of power stage";
CM_ SG_ 1552 NLG5_S_L_T_CPRIM "Output power limited by temperature of primary capacitors";
CM_ SG_ 1552 NLG5_S_L_MO_MAX "Output power limited by maximum output voltage capability of NLG5";
CM_ SG_ 1552 NLG5_S_L_OC_MAX "Output power limited by maximum output current capability of NLG5";
CM_ SG_ 1552 NLG5_S_L_MC_MAX "Output power limited by maximum mains current capability of NLG5";
CM_ SG_ 1552 NLG5_S_L_PMAX "Output power limited by maximum power capability of NLG5";
CM_ SG_ 1552 NLG5_S_L_CP "Output power limited by control pilot signal (SAE J1772)";
CM_ SG_ 1552 NLG5_S_L_PI "Output power limited by analog input 'power indicator' (PI) limit";
CM_ SG_ 1552 NLG5_S_L_MC "Output power limited by mains current limit";
CM_ SG_ 1552 NLG5_S_L_OC "Output power limited by battery output current limit";
CM_ SG_ 1552 NLG5_S_L_OV "Output power limited by battery output voltage limit";
CM_ SG_ 1552 NLG5_S_BPD_II "Bypass detection bit 2; 00: no bypass, 01: DC bypass detected, 10:AC bypass in phase, 11: AC bypass not in phase";
CM_ SG_ 1552 NLG5_S_BPD_I "Bypass detection bit 1; 00: no bypass, 01: DC bypass detected, 10:AC bypass in phase, 11: AC bypass not in phase";
CM_ SG_ 1552 NLG5_S_CP_DT "Control pilot signal (SAE J1772) detected ";
CM_ SG_ 1552 NLG5_S_UM_II "US mains level 2 (240VAC / 60Hz) detected";
CM_ SG_ 1552 NLG5_S_UM_I "US mains level 1 (120VAC / 60Hz) detected";
CM_ SG_ 1552 NLG5_S_EUM "European mains input detected (230V, 50Hz)";
CM_ SG_ 1552 NLG5_S_FAN "Charger cooling fan is active";
CM_ SG_ 1552 NLG5_S_WAR "Warning condition on, i.e. charging power limited due to any limiting condition; red LED is blinking";
CM_ SG_ 1552 NLG5_S_ERR "An error has been detected, red LED is ON, no power is output";
CM_ SG_ 1552 NLG5_S_HE "Indicates if hardware enabled, i.e. a hi or lo signal is fed to the 'Power On' pin (pin3 of control connector)";
CM_ SG_ 1560 NLG5_OC_COM "Desired battery current. Must always contain a valid value in order to keep on charging.";
CM_ SG_ 1560 NLG5_OV_COM "Desired voltage to be output to the battery. Must always contain a valid value in order to keep on charging.";
CM_ SG_ 1560 NLG5_MC_MAX "Maximum current to be drawn from the mains outlet, usually 16A. Must always contain a valid value in order to keep on charging.";
CM_ SG_ 1560 NLG5_C_MR "Enables CP-State C to request mains voltage";
CM_ SG_ 1560 NLG5_C_CP_V "special signal to tell a charging station equipped with the Control Pilot interface (SAE J1772) to switch on the facility's ventilation (in order to get rid of battery gases like hydrogen, e.g.)";
CM_ SG_ 1560 NLG5_C_C_EL "cycle this value 0-1-0 to clear all latched charger errors ";
CM_ SG_ 1560 NLG5_C_C_EN "Must be ON to enable power stage of the charger";
CM_ BO_ 3 "Enable/disable can forwarding to internal bms network";
CM_ BO_ 700 "periodic message containing current can definitions version";
CM_ BO_ 701 "periodic message containing current can definitions version";
CM_ BO_ 702 "periodic message containing current can definitions version";
CM_ BO_ 703 "periodic message containing current can definitions version";
CM_ BO_ 704 "periodic message containing current can definitions version";
CM_ BO_ 705 "periodic message containing current can definitions version";
CM_ BO_ 257 "ambient temperature as send from IMU";
CM_ BO_ 1072 "data logger message";
CM_ BO_ 265 "Ask telemetry to turn on/off and send a tuple containing the current{test, driver, map); only once";
CM_ BO_ 264 "The answer to the steering wheel's message that changes the status of the telemetry";
CM_ BO_ 1801 "System stats of the raspberry pi inside the steering wheel";
CM_ BO_ 772 "Internal pack measured voltages in V";
CM_ BO_ 804 "Cell pack voltage statistics in V";
CM_ BO_ 836 "Current and power supplied by the pack, energy and state of charge of the pack";
CM_ BO_ 868 "Cell temperatures";
CM_ BO_ 36 "Battery-related errors";
CM_ BO_ 260 "Bms Hv debug signals. It sends the error/feedback that sent the bms to safe mode (fatal error or idle)";
CM_ BO_ 32 "override fans speed";
CM_ BO_ 37 "Status of can forwarding to internal bms network";
CM_ BO_ 773 "Status of fans override";
CM_ BO_ 771 "Status of the feedbacks";
CM_ BO_ 516 "Voltage of the feedbacks";
CM_ BO_ 548 "Voltage of the feedbacks";
CM_ BO_ 580 "Voltage of the feedbacks";
CM_ BO_ 803 "Status of the IMD";
CM_ BO_ 84 "BMS status";
CM_ BO_ 82 "Requests a TS status; only once";
CM_ BO_ 83 "Requests a TS status; only once";
CM_ BO_ 258 "Send update of the tuneable values from the steering wheel";
CM_ BO_ 80 "Ask to DAS to change car status; only once";
CM_ BO_ 1026 "Ask to calibrate pedals by specifying which pedal and if the value is the max or min";
CM_ BO_ 1032 "Acknowledge the calibration of a pedal";
CM_ BO_ 81 "Car status, all states managed by the DAS will be send (car status, inverters status)";
CM_ BO_ 40 "DAS errors messages";
CM_ BO_ 777 "Send feedbacks status";
CM_ BO_ 809 "BMS LV internal state";
CM_ BO_ 835 "Currents of AS Battery system, LV Battery and Charger";
CM_ BO_ 867 "LV Voltages for each cell";
CM_ BO_ 899 "Voltage of LV battery pack";
CM_ BO_ 931 "Temperature Â°C for each cell";
CM_ BO_ 963 "Percentage value from 0% to 100% of radiator fans and pumps speed, 8bit";
CM_ BO_ 775 "Set both radiators speed";
CM_ BO_ 807 "Set both pumps speed";
CM_ BO_ 263 "Set the status of the inverter inputs RFE and RUN";
CM_ BO_ 259 "Inverter status";
CM_ BO_ 515 "LV Battery-related errors";
CM_ BO_ 291 "LV Battery health signals";
CM_ BO_ 323 "LV Battery-related errors";
CM_ BO_ 355 "Shutdown status";
CM_ BO_ 1833 "Request to flash the LV BMS via CAN";
CM_ BO_ 1865 "Acknowledge to flash the LV BMS via CAN";
CM_ BO_ 41 "Send a marker to telemetry";
CM_ BO_ 517 "Voltages for each cell";
CM_ BO_ 549 "Cell temperatures";
CM_ BO_ 581 "Cell balancing status";
CM_ BO_ 512 "Set cell balancing status and threshold in mV; only once";
CM_ BO_ 520 "Encoder and inverter speed in rad/sec";
CM_ BO_ 296 "Control output, N*m";
CM_ BO_ 768 "Sends updates on the presence of the handcart";
CM_ BO_ 800 "Setting from handcart to CAN";
CM_ BO_ 832 "Setting from telemetry to handcart";
CM_ BO_ 547 "PTT activation/deactivation status set";
CM_ BO_ 579 "PTT activation/deactivation status";
CM_ BO_ 1027 "Command for manual regen activation";
BA_DEF_  "Bus Speed" STRING ;
BA_DEF_ SG_  "GenSigSendType" ENUM  "Cyclic","OnWrite","OnWriteWithRepetition","OnChange","OnChangeWithRepetition","IfActive","IfActiveWithRepetition","NoSigSendType";
BA_DEF_ BO_  "GenMsgCycleTime" INT 0 0;
BA_DEF_ BO_  "GenMsgSendType" ENUM  "Cyclic","not_used","not_used","not_used","not_used","Cyclic","not_used","IfActive","NoMsgSendType";
BA_DEF_  "DBName" STRING ;
BA_DEF_  "BusType" STRING ;
BA_DEF_DEF_  "Bus Speed" "500k";
BA_DEF_DEF_  "GenSigSendType" "Cyclic";
BA_DEF_DEF_  "GenMsgCycleTime" 0;
BA_DEF_DEF_  "GenMsgSendType" "NoMsgSendType";
BA_DEF_DEF_  "DBName" "";
BA_DEF_DEF_  "BusType" "CAN";
BA_ "DBName" "CANTemplate";
BA_ "GenMsgCycleTime" BO_ 700 1000;
BA_ "GenMsgCycleTime" BO_ 701 1000;
BA_ "GenMsgCycleTime" BO_ 702 1000;
BA_ "GenMsgCycleTime" BO_ 703 1000;
BA_ "GenMsgCycleTime" BO_ 704 1000;
BA_ "GenMsgCycleTime" BO_ 705 1000;
BA_ "GenMsgCycleTime" BO_ 257 1000;
BA_ "GenMsgCycleTime" BO_ 1072 1000;
BA_ "GenMsgCycleTime" BO_ 264 1000;
BA_ "GenMsgCycleTime" BO_ 1801 1000;
BA_ "GenMsgCycleTime" BO_ 772 10;
BA_ "GenMsgCycleTime" BO_ 804 10;
BA_ "GenMsgCycleTime" BO_ 836 10;
BA_ "GenMsgCycleTime" BO_ 868 100;
BA_ "GenMsgCycleTime" BO_ 36 10;
BA_ "GenMsgCycleTime" BO_ 260 200;
BA_ "GenMsgCycleTime" BO_ 84 10;
BA_ "GenMsgCycleTime" BO_ 82 100;
BA_ "GenMsgCycleTime" BO_ 83 100;
BA_ "GenMsgCycleTime" BO_ 258 100;
BA_ "GenMsgCycleTime" BO_ 81 100;
BA_ "GenMsgCycleTime" BO_ 40 10;
BA_ "GenMsgCycleTime" BO_ 777 300;
BA_ "GenMsgCycleTime" BO_ 809 200;
BA_ "GenMsgCycleTime" BO_ 835 300;
BA_ "GenMsgCycleTime" BO_ 867 200;
BA_ "GenMsgCycleTime" BO_ 899 200;
BA_ "GenMsgCycleTime" BO_ 931 200;
BA_ "GenMsgCycleTime" BO_ 963 1000;
BA_ "GenMsgCycleTime" BO_ 263 100;
BA_ "GenMsgCycleTime" BO_ 259 300;
BA_ "GenMsgCycleTime" BO_ 515 300;
BA_ "GenMsgCycleTime" BO_ 291 300;
BA_ "GenMsgCycleTime" BO_ 323 300;
BA_ "GenMsgCycleTime" BO_ 355 500;
BA_ "GenMsgCycleTime" BO_ 1865 50;
BA_ "GenMsgCycleTime" BO_ 517 100;
BA_ "GenMsgCycleTime" BO_ 549 100;
BA_ "GenMsgCycleTime" BO_ 581 500;
BA_ "GenMsgCycleTime" BO_ 520 10;
BA_ "GenMsgCycleTime" BO_ 513 10;
BA_ "GenMsgCycleTime" BO_ 514 10;
BA_ "GenMsgCycleTime" BO_ 385 100;
BA_ "GenMsgCycleTime" BO_ 386 100;
BA_ "GenMsgCycleTime" BO_ 296 100;
BA_ "GenMsgCycleTime" BO_ 768 500;
BA_ "GenMsgCycleTime" BO_ 800 500;
BA_ "GenMsgCycleTime" BO_ 832 500;
BA_ "GenMsgCycleTime" BO_ 1027 100;
VAL_ 3 can_forward_set 0 "OFF" 1 "ON" ;
VAL_ 705 cellboard_id 0 "CELLBOARD_0" 1 "CELLBOARD_1" 2 "CELLBOARD_2" 3 "CELLBOARD_3" 4 "CELLBOARD_4" 5 "CELLBOARD_5" ;
VAL_ 265 tlm_status 0 "OFF" 1 "ON" ;
VAL_ 264 tlm_status 0 "OFF" 1 "ON" ;
VAL_ 32 fans_override 0 "OFF" 1 "ON" ;
VAL_ 37 can_forward_status 0 "OFF" 1 "ON" ;
VAL_ 773 fans_override 0 "OFF" 1 "ON" ;
VAL_ 771 feedback_sd_imd 0 "FEEDBACK_STATE_LOW" 1 "FEEDBACK_STATE_ERROR" 2 "FEEDBACK_STATE_HIGH" ;
VAL_ 771 feedback_sd_bms 0 "FEEDBACK_STATE_LOW" 1 "FEEDBACK_STATE_ERROR" 2 "FEEDBACK_STATE_HIGH" ;
VAL_ 771 feedback_sd_in 0 "FEEDBACK_STATE_LOW" 1 "FEEDBACK_STATE_ERROR" 2 "FEEDBACK_STATE_HIGH" ;
VAL_ 771 feedback_sd_out 0 "FEEDBACK_STATE_LOW" 1 "FEEDBACK_STATE_ERROR" 2 "FEEDBACK_STATE_HIGH" ;
VAL_ 771 feedback_sd_end 0 "FEEDBACK_STATE_LOW" 1 "FEEDBACK_STATE_ERROR" 2 "FEEDBACK_STATE_HIGH" ;
VAL_ 771 feedback_check_mux 0 "FEEDBACK_STATE_LOW" 1 "FEEDBACK_STATE_ERROR" 2 "FEEDBACK_STATE_HIGH" ;
VAL_ 771 feedback_imd_fault 0 "FEEDBACK_STATE_LOW" 1 "FEEDBACK_STATE_ERROR" 2 "FEEDBACK_STATE_HIGH" ;
VAL_ 771 feedback_tsp_over_60v_status 0 "FEEDBACK_STATE_LOW" 1 "FEEDBACK_STATE_ERROR" 2 "FEEDBACK_STATE_HIGH" ;
VAL_ 771 feedback_precharge_status 0 "FEEDBACK_STATE_LOW" 1 "FEEDBACK_STATE_ERROR" 2 "FEEDBACK_STATE_HIGH" ;
VAL_ 771 feedback_airn_gate 0 "FEEDBACK_STATE_LOW" 1 "FEEDBACK_STATE_ERROR" 2 "FEEDBACK_STATE_HIGH" ;
VAL_ 771 feedback_airp_gate 0 "FEEDBACK_STATE_LOW" 1 "FEEDBACK_STATE_ERROR" 2 "FEEDBACK_STATE_HIGH" ;
VAL_ 771 feedback_airp_status 0 "FEEDBACK_STATE_LOW" 1 "FEEDBACK_STATE_ERROR" 2 "FEEDBACK_STATE_HIGH" ;
VAL_ 771 feedback_airn_status 0 "FEEDBACK_STATE_LOW" 1 "FEEDBACK_STATE_ERROR" 2 "FEEDBACK_STATE_HIGH" ;
VAL_ 771 feedback_ts_over_60v_status 0 "FEEDBACK_STATE_LOW" 1 "FEEDBACK_STATE_ERROR" 2 "FEEDBACK_STATE_HIGH" ;
VAL_ 771 feedback_tsal_green 0 "FEEDBACK_STATE_LOW" 1 "FEEDBACK_STATE_ERROR" 2 "FEEDBACK_STATE_HIGH" ;
VAL_ 771 feedback_ext_latched 0 "FEEDBACK_STATE_LOW" 1 "FEEDBACK_STATE_ERROR" 2 "FEEDBACK_STATE_HIGH" ;
VAL_ 771 feedback_bms_cockpit 0 "FEEDBACK_STATE_LOW" 1 "FEEDBACK_STATE_ERROR" 2 "FEEDBACK_STATE_HIGH" ;
VAL_ 771 feedback_tsal_green_fault_latched 0 "FEEDBACK_STATE_LOW" 1 "FEEDBACK_STATE_ERROR" 2 "FEEDBACK_STATE_HIGH" ;
VAL_ 771 feedback_imd_cockpit 0 "FEEDBACK_STATE_LOW" 1 "FEEDBACK_STATE_ERROR" 2 "FEEDBACK_STATE_HIGH" ;
VAL_ 771 feedback_implausibility_detected 0 "FEEDBACK_STATE_LOW" 1 "FEEDBACK_STATE_ERROR" 2 "FEEDBACK_STATE_HIGH" ;
VAL_ 803 imd_status 0 "IMD_SC" 1 "IMD_NORMAL" 2 "IMD_UNDER_VOLTAGE" 3 "IMD_START_MEASURE" 4 "IMD_DEVICE_ERROR" 5 "IMD_EARTH_FAULT" ;
VAL_ 84 ts_status 0 "INIT" 1 "IDLE" 2 "AIRN_CLOSE" 3 "PRECHARGE" 4 "AIRP_CLOSE" 5 "TS_ON" 6 "FATAL_ERROR" ;
VAL_ 82 ts_status_set 0 "OFF" 1 "ON" ;
VAL_ 83 ts_status_set 0 "OFF" 1 "ON" ;
VAL_ 80 car_status_set 0 "IDLE" 1 "READY" 2 "DRIVE" ;
VAL_ 1026 bound 0 "SET_MAX" 1 "SET_MIN" ;
VAL_ 1026 pedal 0 "ACCELERATOR" 1 "BRAKE" ;
VAL_ 1032 bound 0 "SET_MAX" 1 "SET_MIN" ;
VAL_ 1032 pedal 0 "ACCELERATOR" 1 "BRAKE" ;
VAL_ 81 car_status 0 "INIT" 1 "ENABLE_INV_UPDATES" 2 "CHECK_INV_SETTINGS" 3 "IDLE" 4 "START_TS_PRECHARGE" 5 "WAIT_TS_PRECHARGE" 6 "WAIT_DRIVER" 7 "ENABLE_INV_DRIVE" 8 "DRIVE" 9 "DISABLE_INV_DRIVE" 10 "START_TS_DISCHARGE" 11 "WAIT_TS_DISCHARGE" 12 "FATAL_ERROR" ;
VAL_ 81 inverter_r 0 "OFF" 1 "IDLE" 2 "ON" ;
VAL_ 81 inverter_l 0 "OFF" 1 "IDLE" 2 "ON" ;
VAL_ 809 status 0 "INIT" 1 "RUN" 2 "ERROR" ;
VAL_ 263 status 0 "OFF" 1 "ON" ;
VAL_ 259 status 0 "OFF" 1 "ON" ;
VAL_ 1865 response 0 "NO_FLASH" 1 "FLASH" 2 "PREPARING_TO_FLASH" ;
VAL_ 581 balancing_status 0 "OFF" 1 "ON" ;
VAL_ 581 cellboard_id 0 "CELLBOARD_0" 1 "CELLBOARD_1" 2 "CELLBOARD_2" 3 "CELLBOARD_3" 4 "CELLBOARD_4" 5 "CELLBOARD_5" ;
VAL_ 512 set_balancing_status 0 "OFF" 1 "ON" ;
VAL_ 800 status 0 "NONE" 1 "CHECK" 2 "IDLE" 3 "PRECHARGE" 4 "READY" 5 "CHARGE" 6 "CHARGE_DONE" 7 "BALANCING" 8 "ERROR" ;
VAL_ 800 fans_override 0 "OFF" 1 "ON" ;
VAL_ 832 status 0 "NONE" 1 "CHECK" 2 "IDLE" 3 "PRECHARGE" 4 "READY" 5 "CHARGE" 6 "CHARGE_DONE" 7 "BALANCING" 8 "ERROR" ;
VAL_ 832 fans_override 0 "OFF" 1 "ON" ;
VAL_ 547 status 0 "OFF" 1 "ON" ;
VAL_ 579 status 0 "OFF" 1 "ON" ;
VAL_ 1027 status 0 "OFF" 1 "ON" ;
